AUTOSAR XML (schema 314)
package /ComponentType
  internal behavior Sa_TmprlMon2_InternalBehavior: component=Sa_TmprlMon2
    timing event TMT_TmprlMon2_Per1: start-on-event=TmprlMon2_Per1, period=0.002
    port-api-options:
      enable-take-address=false, indirect-api=false, port=SystemTime
      enable-take-address=false, indirect-api=false, port=WdMonitor
    runnable TmprlMon2_Per1  # Periodic function intended to be placed at the beginning of the 2ms task list to create the rising edge of the WdMonitor signal.
      sync call SC_WdMonitor_OP_SET: operation=WdMonitor.OP_SET, timeout=0
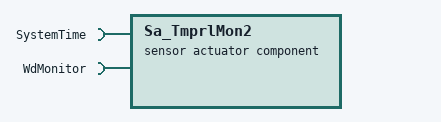
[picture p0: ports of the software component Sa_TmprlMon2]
  sensor actuator software component type Sa_TmprlMon2
    require port SystemTime: required-interface=SystemTime
      required-com-specs:
        DtrmnElapsedTime_mS_u16
        DtrmnElapsedTime_mS_u32
        DtrmnElapsedTime_uS_u16
        DtrmnElapsedTime_uS_u32
        GetSystemTime_mS_u32
        GetSystemTime_uS_u32
    require port WdMonitor: client-com-spec=OP_SET, required-interface=WdMonitor
  swc implementation Sa_TmprlMon2_Implementation: behavior=Sa_TmprlMon2_InternalBehavior
    code-descriptors:
      code Code: type=SRC
